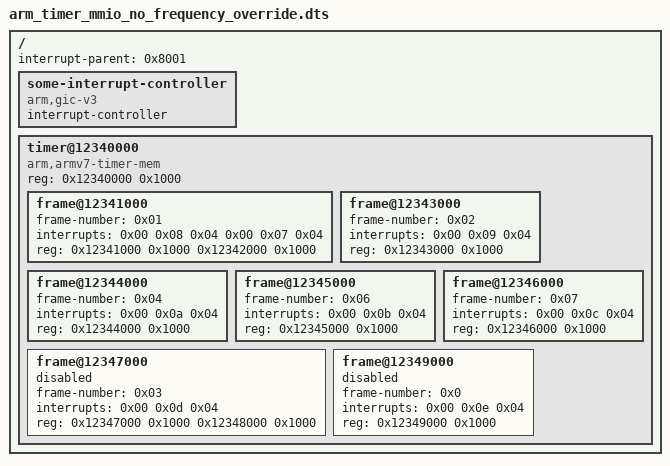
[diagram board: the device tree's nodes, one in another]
// Copyright 2025 The Fuchsia Authors. All rights reserved.
// Use of this source code is governed by a BSD-style license that can be
// found in the LICENSE file.

/dts-v1/;

/ {
    interrupt-parent = <0x8001>;
    #size-cells = <0x01>;
    #address-cells = <0x01>;
    some-interrupt-controller {
        #address-cells = <0x02>;
        #size-cells = <0x02>;
        #interrupt-cells = <0x03>;
        compatible = "arm,gic-v3";
        phandle = <0x8001>;
        interrupt-controller;
    };
    timer@12340000 {
        #address-cells = <0x01>;
        #size-cells = <0x01>;
        ranges;
        compatible = "arm,armv7-timer-mem";
        reg = <0x12340000 0x1000>;
        phandle = <0x192>;

        frame@12341000 {
            frame-number = <0x01>;
            interrupts = <0x00 0x08 0x04 0x00 0x07 0x04>;
            reg = <0x12341000 0x1000 0x12342000 0x1000>;
        };

        frame@12343000 {
            frame-number = <0x02>;
            interrupts = <0x00 0x09 0x04>;
            reg = <0x12343000 0x1000>;
        };

        frame@12344000 {
            frame-number = <0x04>;
            interrupts = <0x00 0x0a 0x04>;
            reg = <0x12344000 0x1000>;
        };

        frame@12345000 {
            frame-number = <0x06>;
            interrupts = <0x00 0x0b 0x04>;
            reg = <0x12345000 0x1000>;
        };

        frame@12346000 {
            frame-number = <0x07>;
            interrupts = <0x00 0x0c 0x04>;
            reg = <0x12346000 0x1000>;
        };

        frame@12347000 {
            frame-number = <0x03>;
            interrupts = <0x00 0x0d 0x04>;
            reg = <0x12347000 0x1000 0x12348000 0x1000>;
            status = "disabled";
        };

        frame@12349000 {
            frame-number = <0x0>;
            interrupts = <0x00 0x0e 0x04>;
            reg = <0x12349000 0x1000>;
            status = "disabled";
        };
    };
};
